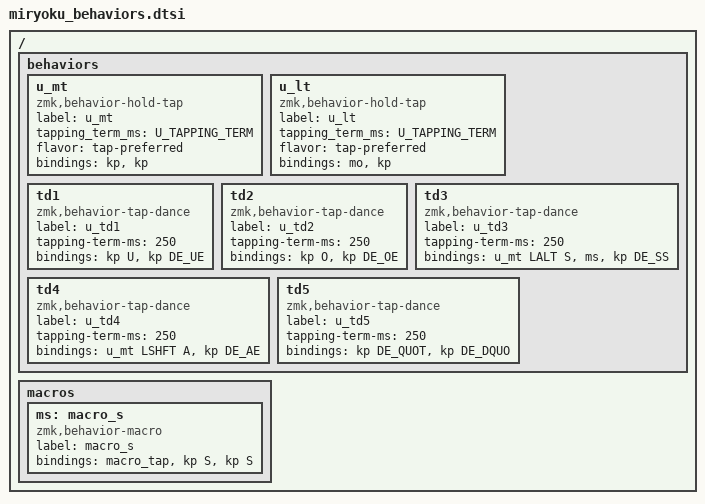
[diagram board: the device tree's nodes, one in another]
// Copyright 2022 Manna Harbour
// https://github.com/manna-harbour/miryoku

/ {
  behaviors {
    u_mt: u_mt {
      compatible = "zmk,behavior-hold-tap";
      label = "u_mt";
      #binding-cells = <2>;
      tapping_term_ms = <U_TAPPING_TERM>;
      flavor = "tap-preferred";
      bindings = <&kp>, <&kp>;
    };
    u_lt: u_lt {
      compatible = "zmk,behavior-hold-tap";
      label = "u_lt";
      #binding-cells = <2>;
      tapping_term_ms = <U_TAPPING_TERM>;
      flavor = "tap-preferred";
      bindings = <&mo>, <&kp>;
    };
    td1: td1 {
      compatible = "zmk,behavior-tap-dance";
      label = "u_td1";
      #binding-cells = <0>;
      tapping-term-ms = <250>;
      bindings = <&kp U>, <&kp DE_UE>;
    };
    td2: td2 {
      compatible = "zmk,behavior-tap-dance";
      label = "u_td2";
      #binding-cells = <0>;
      tapping-term-ms = <250>;
      bindings = <&kp O>, <&kp DE_OE>;
    };
    td3: td3 {
      compatible = "zmk,behavior-tap-dance";
      label = "u_td3";
      #binding-cells = <0>;
      tapping-term-ms = <250>;
      bindings = <&u_mt LALT S>, <&ms>, <&kp DE_SS>;
    };
    td4: td4 {
      compatible = "zmk,behavior-tap-dance";
      label = "u_td4";
      #binding-cells = <0>;
      tapping-term-ms = <250>;
      bindings = <&u_mt LSHFT A>, <&kp DE_AE>;
    };
    td5: td5 {
      compatible = "zmk,behavior-tap-dance";
      label = "u_td5";
      #binding-cells = <0>;
      tapping-term-ms = <250>;
      bindings = <&kp DE_QUOT>, <&kp DE_DQUO>;
    };
  };

  macros {
    ms: macro_s {
      label = "macro_s";
      compatible = "zmk,behavior-macro";
      #binding-cells = <0>;
      bindings = <&macro_tap &kp S &kp S>;
    };
  };
};
